# MK21FA12 register map
Vendor: Freescale Semiconductor, Inc.; Series: Kinetis_K; File version: 1.6
CPU: CM4 r0p1, little endian, no MPU, FPU, VTOR, 4 interrupt priority bits
Registers are 32-bit, read-write, reset 0x0 unless marked. A register's access mark holds for its fields unless they carry their own. Offsets are from the block's base; [hi:lo] are bit positions; {n}, {i} and the like mark numbered series; 'fields as' and 'values as' point back to an identical list.

## OSC — Oscillator
Base 0x40065000; register names take the prefix OSC_
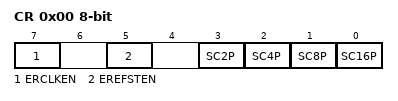
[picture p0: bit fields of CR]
0x00 CR 8-bit — OSC Control Register
  [7] ERCLKEN — External Reference Enable
    0=External reference clock is inactive; 1=External reference clock is enabled
  [5] EREFSTEN — External Reference Stop Enable
    0=External reference clock is disabled in Stop mode; 1=External reference clock stays enabled in Stop mode if ERCLKEN is set before entering Stop mode
  [3] SC2P — Oscillator 2 pF Capacitor Load Configure
    0=Disable the selection; 1=Add 2 pF capacitor to the oscillator load
  [2] SC4P — Oscillator 4 pF Capacitor Load Configure
    0=Disable the selection; 1=Add 4 pF capacitor to the oscillator load
  [1] SC8P — Oscillator 8 pF Capacitor Load Configure
    0=Disable the selection; 1=Add 8 pF capacitor to the oscillator load
  [0] SC16P — Oscillator 16 pF Capacitor Load Configure
    0=Disable the selection; 1=Add 16 pF capacitor to the oscillator load

## VREF — Voltage Reference
Base 0x40074000; register names take the prefix VREF_
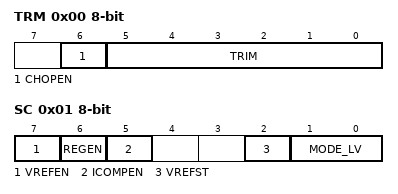
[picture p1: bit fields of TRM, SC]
0x00 TRM 8-bit (reset mask 0x40) — VREF Trim Register
  [6] CHOPEN — Chop oscillator enable. When set, internal chopping operation is enabled and the internal analog offset will be minimized.
    0=Chop oscillator is disabled; 1=Chop oscillator is enabled
  [5:0] TRIM — Trim bits
    0=Min; 63=Max
0x01 SC 8-bit — VREF Status and Control Register
  [7] VREFEN — Internal Voltage Reference enable
    0=The module is disabled; 1=The module is enabled
  [6] REGEN — Regulator enable
    0=Internal 1.75 V regulator is disabled; 1=Internal 1.75 V regulator is enabled
  [5] ICOMPEN — Second order curvature compensation enable
    0=Disabled; 1=Enabled
  [2] VREFST ro — Internal Voltage Reference stable
    0=The module is disabled or not stable; 1=The module is stable
  [1:0] MODE_LV — Buffer Mode selection
    0=Bandgap on only, for stabilization and startup; 1=High power buffer mode enabled; 2=Low-power buffer mode enabled

## LLWU — Low leakage wakeup unit
Base 0x4007C000; register names take the prefix LLWU_
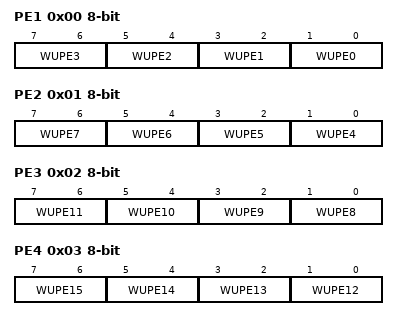
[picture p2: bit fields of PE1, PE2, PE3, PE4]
0x00 PE1 8-bit — LLWU Pin Enable 1 register
  [all] fields
    0=External input pin disabled as wakeup input; 1=External input pin enabled with rising edge detection; 2=External input pin enabled with falling edge detection; 3=External input pin enabled with any change detection
  [2n+1:2n] WUPE{n} (n=0..3) — Wakeup Pin Enable For LLWU_P{n}
0x01 PE2 8-bit — LLWU Pin Enable 2 register
  [all] fields
    values as the fields of PE1
  [2n-7:2n-8] WUPE{n} (n=4..7) — Wakeup Pin Enable For LLWU_P{n}
0x02 PE3 8-bit — LLWU Pin Enable 3 register
  [all] fields
    values as the fields of PE1
  [2n-15:2n-16] WUPE{n} (n=8..11) — Wakeup Pin Enable For LLWU_P{n}
0x03 PE4 8-bit — LLWU Pin Enable 4 register
  [all] fields
    values as the fields of PE1
  [2n-23:2n-24] WUPE{n} (n=12..15) — Wakeup Pin Enable For LLWU_P{n}
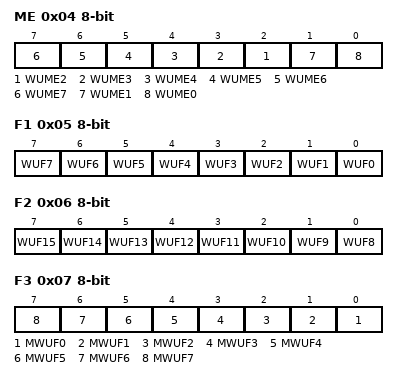
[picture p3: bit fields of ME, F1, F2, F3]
0x04 ME 8-bit — LLWU Module Enable register
  [all] fields
    0=Internal module flag not used as wakeup source; 1=Internal module flag used as wakeup source
  [n] WUME{n} (n=2..7) — Wakeup Module Enable For Module {n}
  [1] WUME1 — Wakeup Module Enable for Module 1
  [0] WUME0 — Wakeup Module Enable For Module 0
0x05 F1 8-bit — LLWU Flag 1 register
  [n] WUF{n} (n=4..7) — Wakeup Flag For LLWU_P{n}
    0=LLWU_P{n} input was not a wakeup source; 1=LLWU_P{n} input was a wakeup source
  [3] WUF3 — Wakeup Flag For LLWU_P3
    0=LLWU_P3 input was not a wake-up source; 1=LLWU_P3 input was a wake-up source
  [2] WUF2 — Wakeup Flag For LLWU_P2
    0=LLWU_P2 input was not a wakeup source; 1=LLWU_P2 input was a wakeup source
  [1] WUF1 — Wakeup Flag For LLWU_P1
    0=LLWU_P1 input was not a wakeup source; 1=LLWU_P1 input was a wakeup source
  [0] WUF0 — Wakeup Flag For LLWU_P0
    0=LLWU_P0 input was not a wakeup source; 1=LLWU_P0 input was a wakeup source
0x06 F2 8-bit — LLWU Flag 2 register
  [n-8] WUF{n} (n=8..15) — Wakeup Flag For LLWU_P{n}
    values as F1.WUF4
0x07 F3 8-bit ro — LLWU Flag 3 register
  [n] MWUF{n} (n=0..7) — Wakeup flag For module {n}
    0=Module {n} input was not a wakeup source; 1=Module {n} input was a wakeup source
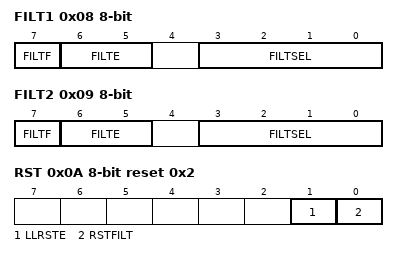
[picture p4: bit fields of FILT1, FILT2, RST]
0x08 FILT1 8-bit — LLWU Pin Filter 1 register
  [7] FILTF — Filter Detect Flag
    0=Pin Filter 1 was not a wakeup source; 1=Pin Filter 1 was a wakeup source
  [6:5] FILTE — Digital Filter On External Pin
    0=Filter disabled; 1=Filter posedge detect enabled; 2=Filter negedge detect enabled; 3=Filter any edge detect enabled
  [3:0] FILTSEL — Filter Pin Select
    0=Select LLWU_P0 for filter; 15=Select LLWU_P15 for filter
0x09 FILT2 8-bit — LLWU Pin Filter 2 register
  [7] FILTF — Filter Detect Flag
    0=Pin Filter 2 was not a wakeup source; 1=Pin Filter 2 was a wakeup source
  [6:5] FILTE — Digital Filter On External Pin
    values as FILT1.FILTE
  [3:0] FILTSEL — Filter Pin Select
    0=Select LLWU_P0 for filter; 15=Select LLWU_P15 for filter
0x0A RST 8-bit reset 0x2 — LLWU Reset Enable register
  [1] LLRSTE — Low-Leakage Mode RESET Enable
    0=RESET pin not enabled as a leakage mode exit source; 1=RESET pin enabled as a low leakage mode exit source
  [0] RSTFILT — Digital Filter On RESET Pin
    0=Filter not enabled; 1=Filter enabled
